# TINY register map
A chip that does not exist, holding one of everything this tool understands.
Registers are 32-bit, read-write, no defined reset value unless marked. A register's access mark holds for its fields unless they carry their own. Offsets are from the block's base; lines under a group give offsets from that group; [hi:lo] are bit positions; {n}, {i} and the like mark numbered series; 'fields as' and 'values as' point back to an identical list; <NAME> marks a mode.

## Memory map
0x40070000 UART0 — A serial port
0x40078000 UART1 — A second serial port
0x50000000 WIDE

## UART0 — A serial port
Base 0x40070000
Same registers: UART1 0x40078000
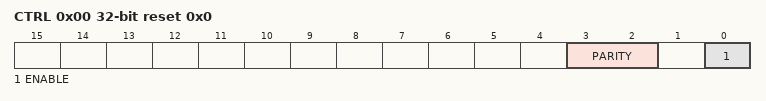
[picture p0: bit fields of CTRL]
0x00 CTRL reset 0x0 — Control
  [3:2] PARITY
    0=NONE (No parity bit); 1=EVEN; 2=odd_parity
  [0] ENABLE — Turns the port on
0x04 DATA
  [7:0] BYTE

## WIDE
Base 0x50000000
0x00 ALL
  [31:0] EVERY
